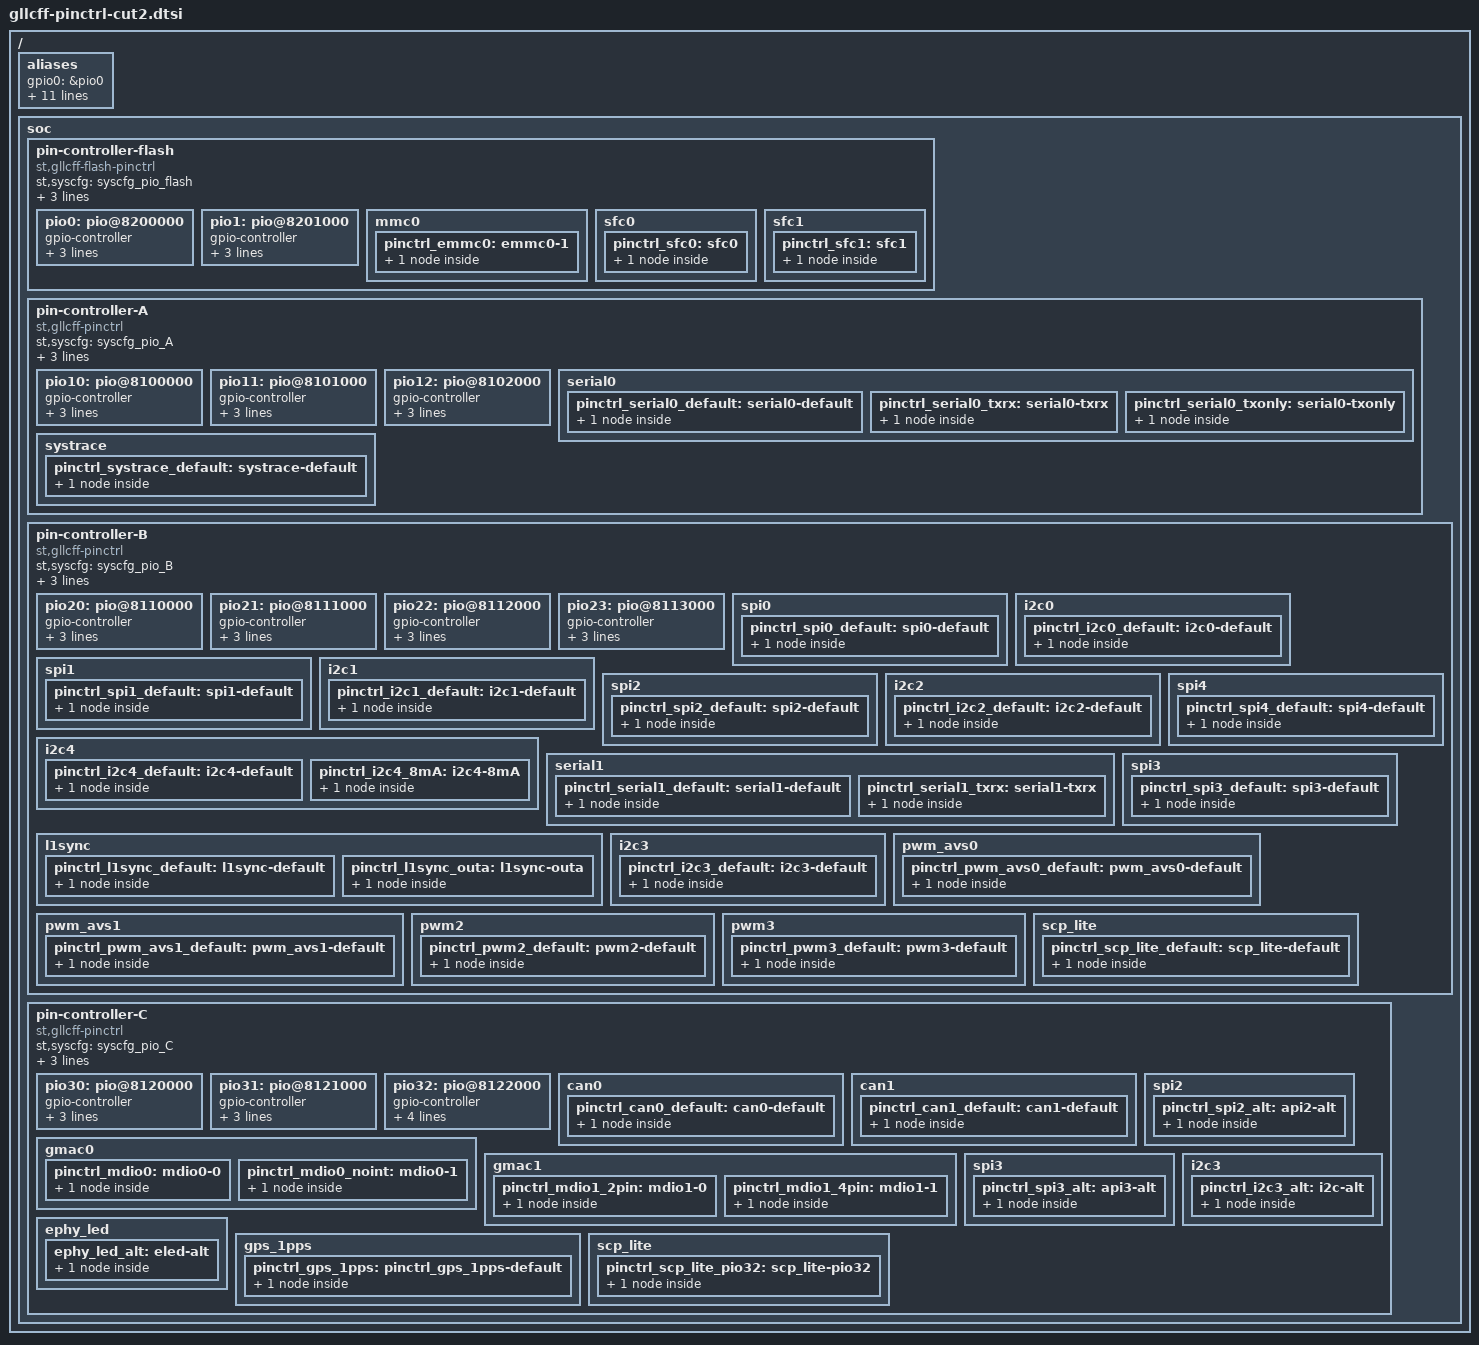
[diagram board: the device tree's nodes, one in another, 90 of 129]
/*
 * Copyright (C) 2018 STMicroelectronics Limited.
 * Author: Carmelo Amoroso <carmelo.amoroso@st.com>
 * Author: Giuseppe Cavallaro <peppe.cavallaro@st.com>
 * Author: Giuseppe Condorelli <giuseppe.condorelli@st.com>
 *
 * This program is free software; you can redistribute it and/or modify
 * it under the terms of the GNU General Public License version 2 as
 * publishhed by the Free Software Foundation.
 */

#include "st-pincfg.h"
#include <dt-bindings/interrupt-controller/arm-gic.h>

/ {
	aliases {
		/* pios for FLASH */
		gpio0 = &pio0;
		gpio1 = &pio1;

		/* pios for FC_BACKBONE Partition A */
		gpio2 = &pio10;
		gpio3 = &pio11;
		gpio4 = &pio12;

		/* pios for FC_BACKBONE Partition B */
		gpio5 = &pio20;
		gpio6 = &pio21;
		gpio7 = &pio22;
		gpio8 = &pio23;

		/* pios for FC_BACKBONE Partition C */
		gpio9 = &pio30;
		gpio10 = &pio31;
		gpio11 = &pio32;
	};

	soc {
		/* pios for FLASH */
		pin-controller-flash {
			#address-cells = <2>;
			#size-cells = <1>;
			compatible = "st,gllcff-flash-pinctrl";
			st,syscfg = <&syscfg_pio_flash>;
			ranges = <0 0 0 0x1e500000 0x2000>;
			st,no-irqmux-reg;
			interrupts = <GIC_SPI 57 IRQ_TYPE_LEVEL_HIGH>;
			interrupts-names = "irqmux";

			pio0: pio@8200000 {
				gpio-controller;
				#gpio-cells = <2>;
				reg = <0x0 0x0 0x100>;
				st,bank-name = "PIO0";
				interrupt-controller;
				#interrupt-cells = <2>;
			};

			pio1: pio@8201000 {
				gpio-controller;
				#gpio-cells = <2>;
				reg = <0x0 0x1000 0x100>;
				st,bank-name = "PIO1";
				interrupt-controller;
				#interrupt-cells = <2>;
			};

			mmc0 {
				pinctrl_emmc0: emmc0-1 {
					st,pins {
						emmc_clk = <&pio0 6 ALT2 BIDIR_PU>;
						emmc_cmd = <&pio0 7 ALT2 BIDIR_PU>;
						emmc_d0 = <&pio1 0 ALT2 BIDIR_PU>;
						emmc_d1 = <&pio1 1 ALT2 BIDIR_PU>;
						emmc_d2 = <&pio1 2 ALT2 BIDIR_PU>;
						emmc_d3 = <&pio1 3 ALT2 BIDIR_PU>;
						emmc_d4 = <&pio1 4 ALT2 BIDIR_PU>;
						emmc_d5 = <&pio1 5 ALT2 BIDIR_PU>;
						emmc_d6 = <&pio1 6 ALT2 BIDIR_PU>;
						emmc_d7 = <&pio1 7 ALT2 BIDIR_PU>;
					};
				};
			};

			sfc0 {
				pinctrl_sfc0: sfc0 {
					st,pins {
						spi-sfc-cs = <&pio0 0 ALT1 BIDIR>;
						spi-sfc-clk = <&pio0 1 ALT1 BIDIR>;
						spi-sfc-d0 = <&pio0 2 ALT1 BIDIR>;
						spi-sfc-d1 = <&pio0 3 ALT1 BIDIR>;
						spi-sfc-d2 = <&pio0 4 ALT1 BIDIR>;
						spi-sfc-d3 = <&pio0 5 ALT1 BIDIR>;
					};
				};
			};

			sfc1 {
				pinctrl_sfc1: sfc1 {
					st,pins {
						spi-sfc-cs = <&pio0 6 ALT1 BIDIR>;
						spi-sfc-clk = <&pio0 7 ALT1 BIDIR>;
						spi-sfc-d0 = <&pio1 0 ALT1 BIDIR>;
						spi-sfc-d1 = <&pio1 1 ALT1 BIDIR>;
						spi-sfc-d2 = <&pio1 2 ALT1 BIDIR>;
						spi-sfc-d3 = <&pio1 3 ALT1 BIDIR>;
					};
				};
			};

		};

		/* BACKBONE Partition A */
		pin-controller-A {
			#address-cells = <2>;
			#size-cells = <1>;
			compatible = "st,gllcff-pinctrl";
			st,syscfg = <&syscfg_pio_A>;
			ranges = <0 0 0 0x8100000 0x3000>;
			st,no-irqmux-reg;
			interrupts = <GIC_SPI 59 IRQ_TYPE_LEVEL_HIGH>;
			interrupts-names = "irqmux";

			pio10: pio@8100000 {
				gpio-controller;
				#gpio-cells = <2>;
				reg = <0x0 0x0 0x100>;
				st,bank-name = "PIO10";
				interrupt-controller;
				#interrupt-cells = <2>;
			};

			pio11: pio@8101000 {
				gpio-controller;
				#gpio-cells = <2>;
				reg = <0x0 0x1000 0x100>;
				st,bank-name = "PIO11";
				interrupt-controller;
				#interrupt-cells = <2>;
			};

			pio12: pio@8102000 {
				gpio-controller;
				#gpio-cells = <2>;
				reg = <0x0 0x2000 0x100>;
				st,bank-name = "PIO12";
				interrupt-controller;
				#interrupt-cells = <2>;
			};

			serial0 {
				pinctrl_serial0_default: serial0-default {
					st,pins {
						tx = <&pio10 0 ALT1 OUT>;
						rx = <&pio10 1 ALT1 IN>;
						cts = <&pio10 2 ALT1 IN>;
						rts = <&pio10 3 ALT1 OUT>;
						txen = <&pio10 4 ALT1 OUT>;
					};
				};
				pinctrl_serial0_txrx: serial0-txrx {
					st,pins {
						tx = <&pio10 0 ALT1 OUT>;
						rx = <&pio10 1 ALT1 IN>;
					};
				};
				/* Explicitly disable RX by configuring it as GPIO */
				pinctrl_serial0_txonly: serial0-txonly {
					st,pins {
						tx = <&pio10 0 ALT1 OUT>;
						rx = <&pio10 1 0 IN>;
					};
				};
			};

			systrace {
				pinctrl_systrace_default: systrace-default {
					st,pins {
						trc_data3 = <&pio11 1 ALT2 OUT
							DE_IO 0 CLK_A>;
						trc_data2 = <&pio11 0 ALT2 OUT
							DE_IO 0 CLK_A>;
						trc_data1 = <&pio10 7 ALT2 OUT
							DE_IO 0 CLK_A>;
						trc_data0 = <&pio10 6 ALT2 OUT
							DE_IO 0 CLK_A>;
						trc_clk = <&pio10 5 ALT2 OUT
							DE_IO 0 CLK_A>;
					};
				};
			};
		};

		/* BACKBONE Partition B */
		pin-controller-B {
			#address-cells = <2>;
			#size-cells = <1>;
			compatible = "st,gllcff-pinctrl";
			st,syscfg = <&syscfg_pio_B>;
			ranges = <0 0 0 0x8110000 0x4000>;
			st,no-irqmux-reg;
			interrupts = <GIC_SPI 61 IRQ_TYPE_LEVEL_HIGH>;
			interrupts-names = "irqmux";

			pio20: pio@8110000 {
				gpio-controller;
				#gpio-cells = <2>;
				reg = <0x0 0x0 0x100>;
				st,bank-name = "PIO20";
				interrupt-controller;
				#interrupt-cells = <2>;
			};

			pio21: pio@8111000 {
				gpio-controller;
				#gpio-cells = <2>;
				reg = <0x0 0x1000 0x100>;
				st,bank-name = "PIO21";
				interrupt-controller;
				#interrupt-cells = <2>;
			};

			pio22: pio@8112000 {
				gpio-controller;
				#gpio-cells = <2>;
				reg = <0x0 0x2000 0x100>;
				st,bank-name = "PIO22";
				interrupt-controller;
				#interrupt-cells = <2>;
			};

			pio23: pio@8113000 {
				gpio-controller;
				#gpio-cells = <2>;
				reg = <0x0 0x3000 0x100>;
				st,bank-name = "PIO23";
				interrupt-controller;
				#interrupt-cells = <2>;
			};

			spi0 {
				pinctrl_spi0_default: spi0-default {
					st,pins {
						mtsr = <&pio20 1 ALT1 OUT>;
						mrst = <&pio20 2 ALT1 IN>;
						scl = <&pio20 0 ALT1 OUT>;
					};
				};
			};

			i2c0 {
				pinctrl_i2c0_default: i2c0-default {
					st,pins {
						sda = <&pio20 1 ALT1 BIDIR>;
						scl = <&pio20 0 ALT1 BIDIR>;
					};
				};
			};

			spi1 {
				pinctrl_spi1_default: spi1-default {
					st,pins {
						mtsr = <&pio20 5 ALT1 OUT>;
						mrst = <&pio20 6 ALT1 IN>;
						scl = <&pio20 4 ALT1 OUT>;
					};
				};
			};

			i2c1 {
				pinctrl_i2c1_default: i2c1-default {
					st,pins {
						sda = <&pio20 5 ALT1 BIDIR>;
						scl = <&pio20 4 ALT1 BIDIR>;
					};
				};
			};

			spi2 {
				pinctrl_spi2_default: spi2-default {
					st,pins {
						mtsr = <&pio21 1 ALT1 (OUT | PAD_DRIVE(4))>;
						mrst = <&pio21 2 ALT1 IN>;
						scl = <&pio21 0 ALT1 (OUT | PAD_DRIVE(4))>;
					};
				};
			};

			i2c2 {
				pinctrl_i2c2_default: i2c2-default {
					st,pins {
						sda = <&pio21 1 ALT1 BIDIR>;
						scl = <&pio21 0 ALT1 BIDIR>;
					};
				};
			};

			i2c4 {
				pinctrl_i2c4_default: i2c4-default {
					st,pins {
						sda = <&pio23 4 ALT1 BIDIR>;
						scl = <&pio23 3 ALT1 BIDIR>;
					};
				};

				pinctrl_i2c4_8mA: i2c4-8mA {
					st,pins {
						sda = <&pio23 4 ALT1 (BIDIR | PAD_DRIVE(4))>;
						scl = <&pio23 3 ALT1 (BIDIR | PAD_DRIVE(4))>;
					};
				};
			};

			spi4 {
				pinctrl_spi4_default: spi4-default {
					st,pins {
						mtsr = <&pio23 4 ALT1 OUT>;
						mrst = <&pio23 5 ALT1 IN>;
						scl = <&pio23 3 ALT1 (OUT | CLK_B)>;
					};
				};
			};

			serial1 {
				pinctrl_serial1_default: serial1-default {
					st,pins {
						tx = <&pio22 5 ALT1 OUT>;
						rx = <&pio22 6 ALT1 IN>;
						cts = <&pio22 7 ALT1 IN>;
						rts = <&pio23 0 ALT1 OUT>;
						txen = <&pio23 1 ALT1 OUT>;
					};
				};
				pinctrl_serial1_txrx: serial1-txrx {
					st,pins {
						tx = <&pio22 5 ALT1 OUT>;
						rx = <&pio22 6 ALT1 IN>;
					};
				};
			};

			l1sync {
				pinctrl_l1sync_default: l1sync-default {
					st,pins {
						l1syncin = <&pio22 0 ALT1 IN>;
						l1syncouta = <&pio22 1 ALT2 OUT BYPASS 0>;
						l1syncoutb = <&pio22 2 ALT2 OUT BYPASS 0>;
					};
				};
				pinctrl_l1sync_outa: l1sync-outa {
					st,pins {
						l1syncouta = <&pio22 1 ALT2 (OUT | PAD_DRIVE(5)) BYPASS 0>;
					};
				};
			};

			spi3 {
				pinctrl_spi3_default: spi3-default {
					st,pins {
						mtsr = <&pio21 5 ALT1 OUT>;
						mrst = <&pio21 6 ALT1 IN>;
						scl = <&pio21 4 ALT1 OUT>;
					};
				};
			};

			i2c3 {
				pinctrl_i2c3_default: i2c3-default {
					st,pins {
						sda = <&pio21 5 ALT1 BIDIR>;
						scl = <&pio21 4 ALT1 BIDIR>;
					};
				};
			};

			pwm_avs0 {
				pinctrl_pwm_avs0_default: pwm_avs0-default {
					st,pins {
						pwm-out = <&pio23 7 ALT1 (OUT | PAD_DRIVE(4))>;
					};
				};
			};

			pwm_avs1 {
				pinctrl_pwm_avs1_default: pwm_avs1-default {
					st,pins {
						pwm-out = <&pio23 6 ALT1 (OUT | PAD_DRIVE(4))>;
					};
				};
			};

			pwm2 {
				pinctrl_pwm2_default: pwm2-default {
					st,pins {
						pwm-out = <&pio22 4 ALT1 OUT>;
					};
				};
			};

			pwm3 {
				pinctrl_pwm3_default: pwm3-default {
					st,pins {
						pwm-out = <&pio22 3 ALT1 OUT>;
					};
				};
			};

			scp_lite {
				pinctrl_scp_lite_default: scp_lite-default {
					st,pins {
						data = <&pio20 2 ALT3 (OUT | PAD_DRIVE(5))>;
					};
				};
			};
		};

		/* BACKBONE Partition C */
		pin-controller-C {
			#address-cells = <2>;
			#size-cells = <1>;
			compatible = "st,gllcff-pinctrl";
			st,syscfg = <&syscfg_pio_C>;
			ranges = <0 0 0 0x8120000 0x3000>;
			st,no-irqmux-reg;
			interrupts = <GIC_SPI 63 IRQ_TYPE_LEVEL_HIGH>;
			interrupts-names = "irqmux";

			pio30: pio@8120000 {
				gpio-controller;
				#gpio-cells = <2>;
				reg = <0x0 0x0 0x100>;
				st,bank-name = "PIO30";
				interrupt-controller;
				#interrupt-cells = <2>;
			};

			pio31: pio@8121000 {
				gpio-controller;
				#gpio-cells = <2>;
				reg = <0x0 0x1000 0x100>;
				st,bank-name = "PIO31";
				interrupt-controller;
				#interrupt-cells = <2>;
			};

			pio32: pio@8122000 {
				gpio-controller;
				#gpio-cells = <2>;
				reg = <0x0 0x2000 0x100>;
				st,bank-name = "PIO32";
				st,bank-pins-nb = <6>;
				interrupt-controller;
				#interrupt-cells = <2>;
			};

			can0 {
				pinctrl_can0_default: can0-default {
					st,pins {
						tx = <&pio30 5 ALT1 OUT>;
						rx = <&pio30 6 ALT1 IN>;
						txen = <&pio30 7 ALT1 OUT>;
					};
				};
			};

			can1 {
				pinctrl_can1_default: can1-default {
					st,pins {
						tx = <&pio31 0 ALT1 OUT>;
						rx = <&pio31 1 ALT1 IN>;
						txen = <&pio31 2 ALT1 OUT>;
					};
				};
			};

			gmac0 {
				pinctrl_mdio0: mdio0-0 {
					st,pins {
						mdio = <&pio30 1 ALT1 BIDIR BYPASS 0>;
						mdc = <&pio30 2 ALT1 OUT NICLK 0 CLK_A>;
						mdint = <&pio30 3 ALT1 IN>;
					};
				};
				pinctrl_mdio0_noint: mdio0-1 {
					st,pins {
						mdio = <&pio30 1 ALT1 (BIDIR | PAD_DRIVE(4)) BYPASS 0>;
						mdc = <&pio30 2 ALT1 (OUT | PAD_DRIVE(4)) BYPASS 0 CLK_A>;
					};
				};
			};

			gmac1 {
				pinctrl_mdio1_2pin: mdio1-0 {
					st,pins {
						mdio = <&pio31 6 ALT1 (BIDIR | PAD_DRIVE(4)) BYPASS 0>;
						mdc = <&pio31 7 ALT1 (OUT | PAD_DRIVE(4)) BYPASS 0 CLK_A>;
						mdint = <&pio32 0 ALT1 IN>;
					};
				};
				pinctrl_mdio1_4pin: mdio1-1 {
					st,pins {
						mdc = <&pio31 7 ALT1 OUT BYPASS 0 CLK_A>;
						mdo = <&pio32 1 ALT1 OUT BYPASS 0>;
						mdi = <&pio31 6 ALT2 IN BYPASS 0>;
						mddir = <&pio31 5 ALT1 OUT BYPASS 0>;
						mdint = <&pio32 0 ALT1 IN>;
					};
				};
			};

			spi2 {
				pinctrl_spi2_alt: api2-alt {
					st,pins {
						mtsr = <&pio30 6 ALT2 OUT>;
						mrst = <&pio30 7 ALT2 IN>;
						scl = <&pio30 5 ALT2 OUT>;
					};
				};
			};

			spi3 {
				pinctrl_spi3_alt: api3-alt {
					st,pins {
						mtsr = <&pio31 1 ALT2 OUT>;
						mrst = <&pio31 2 ALT2 IN>;
						scl = <&pio31 0 ALT2 OUT>;
					};
				};
			};

			i2c3 {
				pinctrl_i2c3_alt: i2c-alt {
					st,pins {
						sda = <&pio31 1 ALT2 BIDIR>;
						scl = <&pio31 0 ALT2 (BIDIR | CLKNOTDATA)>;
					};
				};
			};

			ephy_led {
				ephy_led_alt: eled-alt {
					st,pins {
						led0 = <&pio30 0 ALT3 OUT>;
						led1 = <&pio30 4 ALT3 OUT>;
					};
				};
			};

			gps_1pps {
				pinctrl_gps_1pps: pinctrl_gps_1pps-default {
					st,pins {
						1pps_in = <&pio31 3 ALT1 IN>;
					};
				};
			};

			scp_lite {
				pinctrl_scp_lite_pio32: scp_lite-pio32 {
					st,pins {
						data = <&pio32 2 ALT1 (OUT | PAD_DRIVE(5))>;
					};
				};
			};
		};
	};
};
